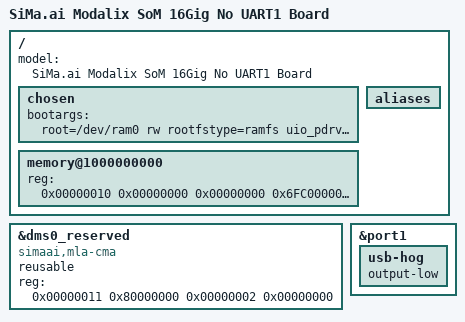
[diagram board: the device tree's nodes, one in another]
// SPDX-License-Identifier: (GPL-2.0+ OR MIT)
/*
 * Copyright (c) 2026 SiMa ai
 */

/dts-v1/;

#include "modalix.dtsi"
#include "modalix-som-common.dtsi"

/ {
	model = "SiMa.ai Modalix SoM 16Gig No UART1 Board";

	/*
	 * Headless variant: board "UART1" (uart12, ttyS0) is repurposed
	 * as a device UART.  It stays enabled, but nothing may claim it
	 * as a console, so no console= in bootargs and no console alias.
	 */
	chosen {
		bootargs = "root=/dev/ram0 rw rootfstype=ramfs uio_pdrv_genirq.of_id=generic-uio";
	};

	aliases {
		/delete-property/ console;
	};

	memory@1000000000 {
		device_type = "memory";
		reg = < 0x00000010 0x00000000 0x00000000 0x6FC00000
				0x00000010 0x75000000 0x00000003 0x0B000000>;
	};
};

&dms0_reserved {
	/* Opt-in reusable: CMA may lend unallocated MLA DMA pages back to Linux.
	 * Switch the heap ABI from the carveout default to the reusable SiMa DMS
	 * pool and drop no-map; the memory node above is extended to cover this
	 * range. mla-rt still matches the "dms@" child by name, so the inherited
	 * node name is left unchanged.
	 */
	compatible = "simaai,mla-cma", "shared-dma-pool";
	/delete-property/ no-map;
	reusable;
	// 8GiB for DMS0 region
	reg = <0x00000011 0x80000000 0x00000002 0x00000000>;
};

/*
 * Drive SIO1 GPIO2 (the usb_uart12 line) low to enable USB host on this
 * board; the shared SoM default hogs it high.
 */
&port1 {
	usb-hog {
		/delete-property/ output-high;
		output-low;
	};
};
